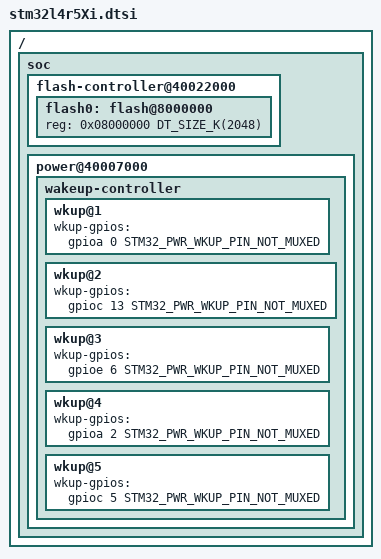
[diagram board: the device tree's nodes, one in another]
/*
 * Copyright (c) 2018 Pushpal Sidhu
 * Copyright (c) 2024 STMicroelectronics
 *
 * SPDX-License-Identifier: Apache-2.0
 */

#include <st/l4/stm32l4r5.dtsi>

/ {
	soc {
		flash-controller@40022000 {
			flash0: flash@8000000 {
				reg = <0x08000000 DT_SIZE_K(2048)>;
				ranges = <0 0x8000000 DT_SIZE_K(2048)>;
			};
		};

		power@40007000 {
			wakeup-controller {
				wkup@1 {
					wkup-gpios = <&gpioa 0 STM32_PWR_WKUP_PIN_NOT_MUXED>;
				};

				wkup@2 {
					wkup-gpios = <&gpioc 13 STM32_PWR_WKUP_PIN_NOT_MUXED>;
				};

				wkup@3 {
					wkup-gpios = <&gpioe 6 STM32_PWR_WKUP_PIN_NOT_MUXED>;
				};

				wkup@4 {
					wkup-gpios = <&gpioa 2 STM32_PWR_WKUP_PIN_NOT_MUXED>;
				};

				wkup@5 {
					wkup-gpios = <&gpioc 5 STM32_PWR_WKUP_PIN_NOT_MUXED>;
				};
			};
		};
	};
};
